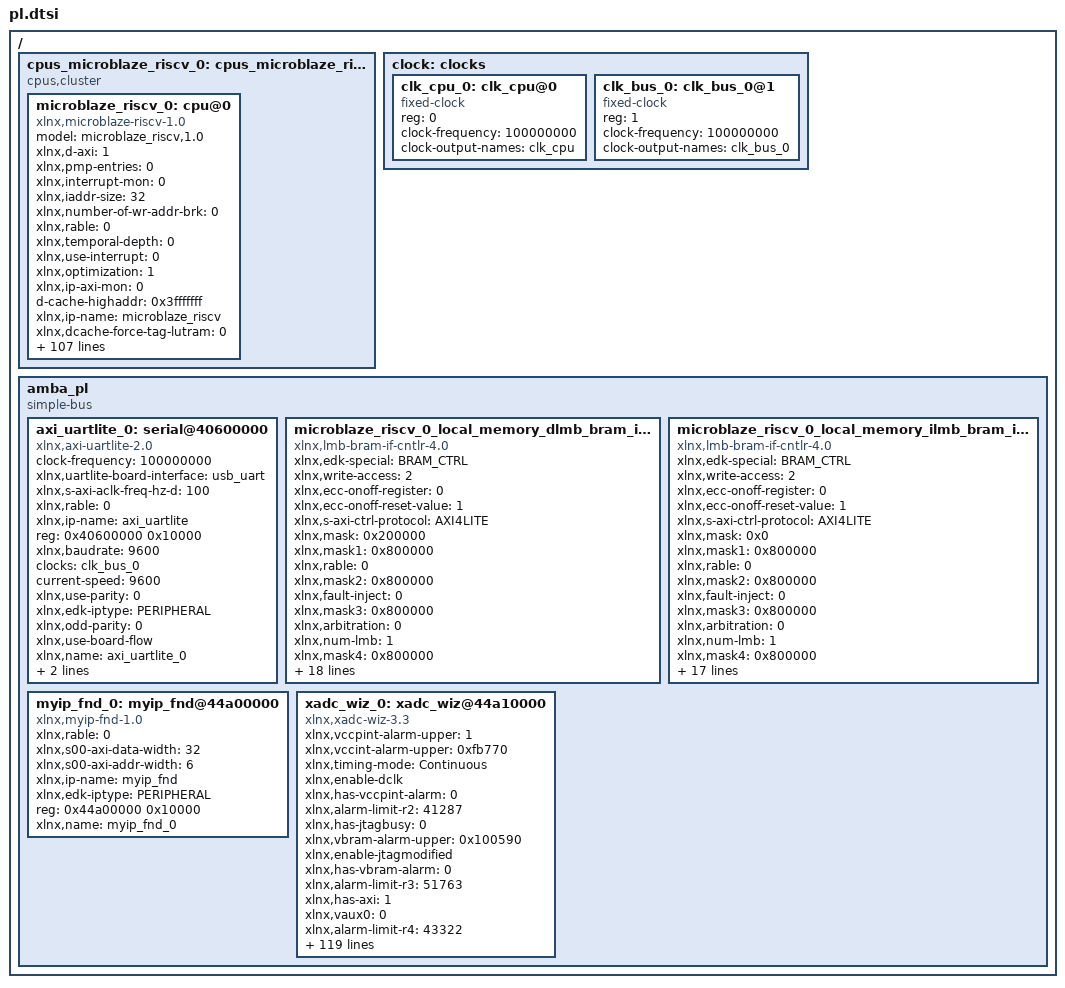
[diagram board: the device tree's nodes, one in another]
/ {
	cpus_microblaze_riscv_0: cpus_microblaze_riscv@0 {
		#cpu-mask-cells = <1>;
		compatible = "cpus,cluster";
		#address-cells = <1>;
		#size-cells = <0>;
		microblaze_riscv_0: cpu@0 {
			model = "microblaze_riscv,1.0";
			xlnx,d-axi = <1>;
			xlnx,pmp-entries = <0>;
			xlnx,interrupt-mon = <0>;
			xlnx,iaddr-size = <32>;
			xlnx,number-of-wr-addr-brk = <0>;
			xlnx,rable = <0>;
			xlnx,temporal-depth = <0>;
			xlnx,use-interrupt = <0>;
			xlnx,optimization = <1>;
			xlnx,ip-axi-mon = <0>;
			d-cache-highaddr = <0x3fffffff>;
			xlnx,ip-name = "microblaze_riscv";
			xlnx,dcache-force-tag-lutram = <0>;
			xlnx,pc-width = <17>;
			xlnx,interrupt-is-edge = <0>;
			reg = <0x0>;
			xlnx,async-interrupt = <1>;
			xlnx,use-mmu = <0>;
			xlnx,icache-victims = <0>;
			xlnx,use-bitman-a = <0>;
			xlnx,d-lmb-mon = <0>;
			xlnx,d-lmb-protocol = <0>;
			xlnx,use-bitman-b = <0>;
			xlnx,use-bitman-c = <0>;
			xlnx,dc-axi-mon = <0>;
			xlnx,debug-trace-async-reset = <0>;
			xlnx,trace = <0>;
			xlnx,part = "xc7a35tcpg236-1";
			xlnx,use-config-reset = <0>;
			xlnx,i-lmb-mon = <0>;
			xlnx,dcache-byte-size = <4096>;
			xlnx,ill-instr-exception = <1>;
			compatible = "xlnx,microblaze-riscv-1.0" , "xlnx,microblaze_riscv";
			xlnx,data-size = <32>;
			xlnx,fault-tolerant = <0>;
			xlnx,use-sleep = <0>;
			xlnx,debug-trace-size = <0>;
			xlnx,pmp-granularity = <2>;
			xlnx,mmu-privileged-instr = <0>;
			d-cache-line-size = <16>;
			xlnx,d-lmb = <1>;
			xlnx,enable-discrete-ports = <0>;
			clock-frequency = <100000000>;
			xlnx,debug-interface = <0>;
			xlnx,use-ext-brk = <0>;
			xlnx,daddr-size = <32>;
			xlnx,debug-enabled = <1>;
			xlnx,num-sync-ff-dbg-trace-clk = <2>;
			xlnx,i-lmb-protocol = <0>;
			xlnx,fsl-exception = <0>;
			xlnx,use-extended-fsl-instr = <0>;
			xlnx,dp-axi-mon = <0>;
			xlnx,impid = <0x1>;
			device_type = "cpu";
			xlnx,branch-target-cache-size = <0>;
			xlnx,dcache-use-writeback = <0>;
			xlnx,use-bitman-s = <0>;
			bus-handle = <&amba_pl>;
			xlnx,icache-line-len = <4>;
			xlnx,base-vectors = <0x0>;
			xlnx,ecc-use-ce-exception = <0>;
			xlnx,edk-special = "microblaze_riscv";
			xlnx,use-dcache = <0>;
			xlnx,use-barrel = <1>;
			xlnx,use-muldiv = <2>;
			xlnx,addr-size = <32>;
			xlnx,debug-external-trace = <0>;
			xlnx,piaddr-size = <32>;
			xlnx,misaligned-exceptions = <1>;
			xlnx,use-bitman = <0>;
			xlnx,num-sync-ff-clk-debug = <2>;
			xlnx,debug-event-counters = <0>;
			xlnx,use-atomic = <0>;
			xlnx,i-axi = <0>;
			xlnx,g-template-list = <1>;
			xlnx,icache-streams = <0>;
			xlnx,dcache-line-len = <4>;
			xlnx,num-sync-ff-clk = <2>;
			xlnx,edk-iptype = "PROCESSOR";
			xlnx,num-sync-ff-dbg-clk = <1>;
			xlnx,interconnect = <2>;
			xlnx,hartid = <0x0>;
			xlnx,debug-latency-counters = <0>;
			xlnx,use-fpu = <0>;
			xlnx,icache-byte-size = <4096>;
			xlnx,edge-is-positive = <1>;
			xlnx,use-icache = <0>;
			d-cache-size = <4096>;
			xlnx,memory-ip-list = "microblaze_riscv_0_local_memory_dlmb_bram_if_cntlr_memory" , "microblaze_riscv_0_local_memory_ilmb_bram_if_cntlr_memory";
			xlnx,async-wakeup = <3>;
			xlnx,use-non-secure = <0>;
			xlnx,s-axi = <0>;
			xlnx,number-of-rd-addr-brk = <0>;
			d-cache-baseaddr = <0x0>;
			xlnx,use-compression = <1>;
			xlnx,avoid-primitives = <0>;
			xlnx,use-counters = <1>;
			xlnx,lockstep-slave = <0>;
			xlnx,use-ext-nm-brk = <0>;
			xlnx,pdaddr-size = <32>;
			xlnx,instr-size = <32>;
			xlnx,i-lmb = <1>;
			xlnx,lockstep-select = <0>;
			xlnx,lmb-data-size = <32>;
			xlnx,ic-axi-mon = <0>;
			xlnx,num-sync-ff-clk-irq = <1>;
			xlnx,fsl-links = <0>;
			timebase-frequency = <100000000>;
			xlnx,archid = <0x1>;
			xlnx,icache-force-tag-lutram = <0>;
			xlnx,dcache-data-width = <0>;
			xlnx,dcache-victims = <0>;
			xlnx,use-branch-target-cache = <0>;
			xlnx,debug-profile-size = <0>;
			xlnx,lockstep-master = <0>;
			xlnx,freq = <100000000>;
			xlnx,number-of-pc-brk = <1>;
			xlnx,imprecise-exceptions = <0>;
			xlnx,icache-data-width = <0>;
			xlnx,debug-counter-width = <64>;
		};
	};
	clock: clocks {
		#address-cells = <1>;
		#size-cells = <0>;
		clk_cpu_0: clk_cpu@0 {
			compatible = "fixed-clock";
			reg = <0>;
			clock-frequency = <100000000>;
			clock-output-names = "clk_cpu";
			#clock-cells = <0>;
		};
		clk_bus_0: clk_bus_0@1 {
			compatible = "fixed-clock";
			reg = <1>;
			clock-frequency = <100000000>;
			clock-output-names = "clk_bus_0";
			#clock-cells = <0>;
		};
	};
	amba_pl: amba_pl {
		ranges;
		compatible = "simple-bus";
		#address-cells = <1>;
		#size-cells = <1>;
		axi_uartlite_0: serial@40600000 {
			compatible = "xlnx,axi-uartlite-2.0" , "xlnx,xps-uartlite-1.00.a";
			clock-frequency = <100000000>;
			xlnx,uartlite-board-interface = "usb_uart";
			xlnx,s-axi-aclk-freq-hz-d = <100>;
			xlnx,rable = <0>;
			xlnx,ip-name = "axi_uartlite";
			reg = <0x40600000 0x10000>;
			xlnx,baudrate = <9600>;
			clocks = <&clk_bus_0>;
			current-speed = <9600>;
			xlnx,use-parity = <0>;
			xlnx,edk-iptype = "PERIPHERAL";
			xlnx,odd-parity = <0>;
			status = "okay";
			xlnx,use-board-flow;
			xlnx,name = "axi_uartlite_0";
			xlnx,data-bits = <8>;
			xlnx,parity = "No_Parity";
		};
		microblaze_riscv_0_local_memory_dlmb_bram_if_cntlr: lmb_bram_if_cntlr@0 {
			xlnx,edk-special = "BRAM_CTRL";
			xlnx,write-access = <2>;
			compatible = "xlnx,lmb-bram-if-cntlr-4.0";
			xlnx,ecc-onoff-register = <0>;
			xlnx,ecc-onoff-reset-value = <1>;
			xlnx,s-axi-ctrl-protocol = "AXI4LITE";
			xlnx,mask = <0x200000>;
			xlnx,mask1 = <0x800000>;
			xlnx,rable = <0>;
			xlnx,mask2 = <0x800000>;
			xlnx,fault-inject = <0>;
			xlnx,mask3 = <0x800000>;
			xlnx,arbitration = <0>;
			xlnx,num-lmb = <1>;
			xlnx,mask4 = <0x800000>;
			reg = <0x00000000 0x20000>;
			xlnx,s-axi-ctrl-addr-width = <32>;
			xlnx,mask5 = <0x800000>;
			xlnx,ecc-status-registers = <0>;
			xlnx,mask6 = <0x800000>;
			xlnx,lmb-protocol = <0>;
			xlnx,ce-counter-width = <0>;
			xlnx,mask7 = <0x800000>;
			xlnx,ecc = <0>;
			xlnx,edk-iptype = "PERIPHERAL";
			xlnx,lmb-dwidth = <32>;
			xlnx,ce-failing-registers = <0>;
			xlnx,interconnect = <0>;
			xlnx,ue-failing-registers = <0>;
			xlnx,data-width = <32>;
			xlnx,s-axi-ctrl-data-width = <32>;
			xlnx,bram-awidth = <32>;
			xlnx,lmb-awidth = <32>;
		};
		microblaze_riscv_0_local_memory_ilmb_bram_if_cntlr: lmb_bram_if_cntlr@1 {
			xlnx,edk-special = "BRAM_CTRL";
			xlnx,write-access = <2>;
			compatible = "xlnx,lmb-bram-if-cntlr-4.0";
			xlnx,ecc-onoff-register = <0>;
			xlnx,ecc-onoff-reset-value = <1>;
			xlnx,s-axi-ctrl-protocol = "AXI4LITE";
			xlnx,mask = <0x0>;
			xlnx,mask1 = <0x800000>;
			xlnx,rable = <0>;
			xlnx,mask2 = <0x800000>;
			xlnx,fault-inject = <0>;
			xlnx,mask3 = <0x800000>;
			xlnx,arbitration = <0>;
			xlnx,num-lmb = <1>;
			xlnx,mask4 = <0x800000>;
			reg = <0x00000000 0x20000>;
			xlnx,s-axi-ctrl-addr-width = <32>;
			xlnx,mask5 = <0x800000>;
			xlnx,ecc-status-registers = <0>;
			xlnx,mask6 = <0x800000>;
			xlnx,lmb-protocol = <0>;
			xlnx,ce-counter-width = <0>;
			xlnx,mask7 = <0x800000>;
			xlnx,ecc = <0>;
			xlnx,edk-iptype = "PERIPHERAL";
			xlnx,lmb-dwidth = <32>;
			xlnx,ce-failing-registers = <0>;
			xlnx,interconnect = <0>;
			xlnx,ue-failing-registers = <0>;
			xlnx,s-axi-ctrl-data-width = <32>;
			xlnx,bram-awidth = <32>;
			xlnx,lmb-awidth = <32>;
		};
		myip_fnd_0: myip_fnd@44a00000 {
			xlnx,rable = <0>;
			xlnx,s00-axi-data-width = <32>;
			compatible = "xlnx,myip-fnd-1.0";
			status = "okay";
			xlnx,s00-axi-addr-width = <6>;
			xlnx,ip-name = "myip_fnd";
			xlnx,edk-iptype = "PERIPHERAL";
			reg = <0x44a00000 0x10000>;
			xlnx,name = "myip_fnd_0";
		};
		xadc_wiz_0: xadc_wiz@44a10000 {
			xlnx,vccpint-alarm-upper = <1>;
			xlnx,vccint-alarm-upper = <0xfb770>;
			xlnx,timing-mode = "Continuous";
			xlnx,enable-dclk;
			xlnx,has-vccpint-alarm = <0>;
			xlnx,alarm-limit-r2 = <41287>;
			xlnx,has-jtagbusy = <0>;
			xlnx,vbram-alarm-upper = <0x100590>;
			xlnx,enable-jtagmodified;
			xlnx,has-vbram-alarm = <0>;
			xlnx,alarm-limit-r3 = <51763>;
			xlnx,has-axi = <1>;
			xlnx,vaux0 = <0>;
			xlnx,alarm-limit-r4 = <43322>;
			xlnx,has-busy = <1>;
			xlnx,enable-channel;
			xlnx,vaux1 = <0>;
			xlnx,has-vccaux-alarm = <0>;
			xlnx,alarm-limit-r5 = <21190>;
			xlnx,dclk-frequency = <100>;
			xlnx,rable = <0>;
			xlnx,vaux2 = <0>;
			xlnx,alarm-limit-r6 = <38229>;
			xlnx,vaux3 = <0>;
			xlnx,ip-name = "xadc_wiz";
			xlnx,alarm-limit-r7 = <44622>;
			xlnx,configuration-r0 = <12288>;
			xlnx,has-drp = <0>;
			xlnx,vaux4 = <0>;
			xlnx,sim-file-rel-path = "./";
			reg = <0x44a10000 0x10000>;
			xlnx,alarm-limit-r8 = <22937>;
			xlnx,configuration-r1 = <8463>;
			xlnx,external-mux-channel = "VP_VN";
			xlnx,temperature-alarm-trigger = <85>;
			xlnx,vaux5 = <0>;
			xlnx,alarm-limit-r9 = <20753>;
			xlnx,configuration-r2 = <1024>;
			xlnx,has-jtaglocked = <0>;
			xlnx,vaux6 = <1>;
			xlnx,vaux7 = <0>;
			xlnx,vaux8 = <0>;
			xlnx,vaux9 = <0>;
			xlnx,vaux10 = <0>;
			xlnx,has-vn = <1>;
			xlnx,has-vccpaux-alarm = <0>;
			xlnx,acquisition-time = <4>;
			xlnx,vaux11 = <0>;
			xlnx,has-temp-bus = <0>;
			xlnx,xadc-starup-selection = "channel_sequencer";
			xlnx,enable-busy;
			xlnx,data-width = <32>;
			xlnx,vaux12 = <0>;
			xlnx,sim-file-sel = "Default";
			xlnx,has-vp = <1>;
			xlnx,channel-enable-vauxp14-vauxn14;
			xlnx,ip-type = <0x0>;
			xlnx,temperature-alarm-ot-reset = <70>;
			xlnx,vaux13 = <0>;
			xlnx,enable-convst;
			xlnx,vaux14 = <1>;
			xlnx,vccpaux-alarm-lower = <0x1a17b0>;
			xlnx,vccaux-alarm-lower = <0x1ab3f0>;
			xlnx,vaux15 = <0>;
			compatible = "xlnx,xadc-wiz-3.3" , "xlnx,axi-xadc-1.00.a";
			xlnx,has-external-mux = <0>;
			xlnx,sampling-rate = <0x000000df 0xe0288f62>;
			xlnx,has-reset = <0>;
			xlnx,adc-conversion-rate = <1000>;
			clock-frequency = <100000000>;
			xlnx,vccddro-alarm-lower = <0x118c30>;
			xlnx,enable-calibration-averaging;
			xlnx,has-user-temp-alarm = <0>;
			xlnx,has-ot-alarm = <0>;
			xlnx,has-convst = <0>;
			xlnx,single-channel-selection = "TEMPERATURE";
			xlnx,startup-channel-selection = "single_channel";
			xlnx,interface-selection = "Enable_AXI";
			xlnx,vccpaux-alarm-upper = <0x1b7740>;
			xlnx,vccaux-alarm-upper = <0x1cd6d0>;
			status = "okay";
			xlnx,vccddro-alarm-upper = <0x1312d0>;
			xlnx,name = "xadc_wiz_0";
			xlnx,external-mux = "none";
			xlnx,enable-eoc;
			xlnx,enable-jtaglocked;
			xlnx,sim-file-name = "design";
			xlnx,temperature-alarm-reset = <60>;
			xlnx,addr-width = <32>;
			clocks = <&clk_bus_0>;
			xlnx,alarm-limit-r10 = <21845>;
			xlnx,alarm-limit-r11 = <20753>;
			xlnx,alarm-limit-r12 = <39321>;
			xlnx,edk-iptype = "PERIPHERAL";
			xlnx,alarm-limit-r13 = <37355>;
			xlnx,sequencer-mode = "Continuous";
			xlnx,enable-jtagbusy;
			xlnx,alarm-limit-r14 = <27306>;
			xlnx,include-intr = <1>;
			xlnx,alarm-limit-r15 = <25122>;
			xlnx,fifo-depth = <7>;
			xlnx,has-eoc = <1>;
			xlnx,temperature-alarm-ot-trigger = <125>;
			xlnx,has-channel = <1>;
			xlnx,enable-eos;
			xlnx,vccpint-alarm-lower = <0xe7ef0>;
			xlnx,vccint-alarm-lower = <0xecd10>;
			xlnx,has-dclk = <1>;
			xlnx,vbram-alarm-lower = <0xe7ef0>;
			xlnx,num-wave = <1>;
			xlnx,sequence-r0 = <0>;
			xlnx,has-jtagmodified = <0>;
			xlnx,sequence-r1 = <16448>;
			xlnx,channel-enable-vauxp6-vauxn6;
			xlnx,enable-drp;
			xlnx,sequence-r2 = <0>;
			xlnx,has-vccint-alarm = <0>;
			xlnx,channel-averaging = <256>;
			xlnx,sequence-r3 = <0>;
			xlnx,has-axi4stream = <0>;
			xlnx,sequence-r4 = <0>;
			xlnx,sequence-r5 = <0>;
			xlnx,waveform-type = "CONSTANT";
			xlnx,sequence-r6 = <0>;
			xlnx,vccddro-volt = "1_2";
			xlnx,sequence-r7 = <0>;
			xlnx,has-vccddro-alarm = <0>;
			xlnx,alarm-limit-r0 = <46573>;
			xlnx,has-convstclk = <0>;
			xlnx,has-eos = <1>;
			xlnx,stimulus-freq = <1>;
			xlnx,single-channel-enable-calibration;
			xlnx,alarm-limit-r1 = <22500>;
			xlnx,component-name = "soc_adc_new_xadc_wiz_0_0";
			xlnx,external-muxaddr-enable = <0>;
		};
	};
};
